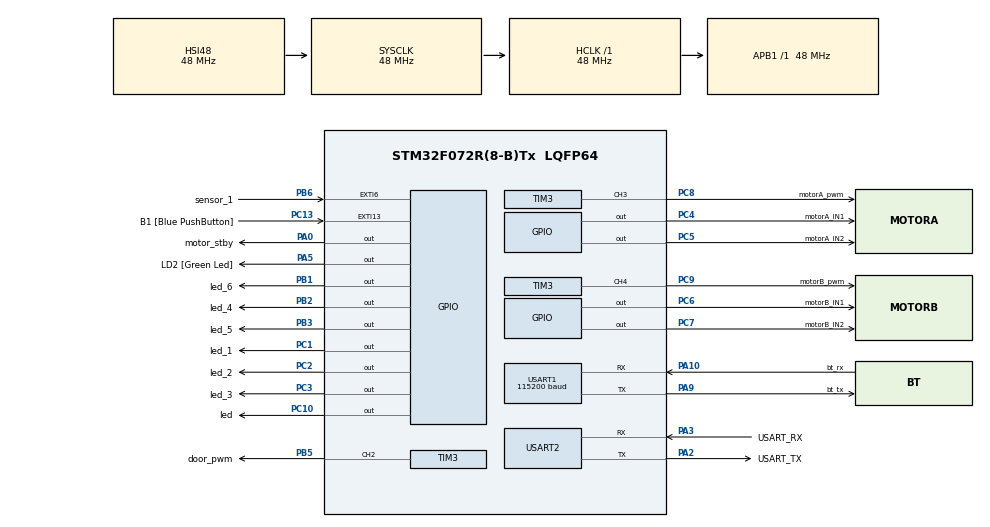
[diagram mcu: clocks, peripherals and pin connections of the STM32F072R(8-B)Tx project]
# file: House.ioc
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Mcu.Family=STM32F0
Mcu.Name=STM32F072R(8-B)Tx
Mcu.Package=LQFP64
NVIC.EXTI4_15_IRQn=true\:3\:0\:true\:false\:true\:true\:false
NVIC.USART1_IRQn=true\:3\:0\:true\:false\:true\:true\:false
PA0.GPIO_Label=motor_stby
PA0.PinState=GPIO_PIN_SET
PA0.Signal=GPIO_Output
PA10.GPIO_Label=bt_rx
PA10.Mode=Asynchronous
PA10.Signal=USART1_RX
PA13.GPIO_Label=TMS
PA13.Mode=Serial_Wire
PA13.Signal=SYS_SWDIO
PA14.GPIO_Label=TCK
PA14.Mode=Serial_Wire
PA14.Signal=SYS_SWCLK
PA2.GPIO_Label=USART_TX
PA2.GPIO_Mode=GPIO_MODE_AF_PP
PA2.GPIO_PuPd=GPIO_NOPULL
PA2.GPIO_Speed=GPIO_SPEED_FREQ_LOW
PA2.Mode=Asynchronous
PA2.Signal=USART2_TX
PA3.GPIO_Label=USART_RX
PA3.GPIO_Mode=GPIO_MODE_AF_PP
PA3.GPIO_PuPd=GPIO_NOPULL
PA3.GPIO_Speed=GPIO_SPEED_FREQ_LOW
PA3.Mode=Asynchronous
PA3.Signal=USART2_RX
PA5.GPIO_Label=LD2 [Green Led]
PA5.GPIO_Mode=GPIO_MODE_OUTPUT_PP
PA5.GPIO_PuPd=GPIO_NOPULL
PA5.GPIO_Speed=GPIO_SPEED_FREQ_LOW
PA5.Signal=GPIO_Output
PA9.GPIO_Label=bt_tx
PA9.Mode=Asynchronous
PA9.Signal=USART1_TX
PB1.GPIO_Label=led_6
PB1.Signal=GPIO_Output
PB2.GPIO_Label=led_4
PB2.GPIO_Speed=GPIO_SPEED_FREQ_LOW
PB2.Signal=GPIO_Output
PB3.GPIO_Label=led_5
PB3.Signal=GPIO_Output
PB5.GPIO_Label=door_pwm
PB5.Signal=S_TIM3_CH2
PB6.GPIO_Label=sensor_1
PB6.GPIO_ModeDefaultEXTI=GPIO_MODE_IT_RISING_FALLING
PB6.Signal=GPXTI6
PC1.GPIO_Label=led_1
PC1.GPIO_Speed=GPIO_SPEED_FREQ_LOW
PC1.Signal=GPIO_Output
PC10.GPIO_Label=led
PC10.Signal=GPIO_Output
PC13.GPIO_Label=B1 [Blue PushButton]
PC13.GPIO_ModeDefaultEXTI=GPIO_MODE_IT_FALLING
PC13.Signal=GPXTI13
PC14-OSC32_IN.Mode=LSE-External-Oscillator
PC14-OSC32_IN.Signal=RCC_OSC32_IN
PC15-OSC32_OUT.Mode=LSE-External-Oscillator
PC15-OSC32_OUT.Signal=RCC_OSC32_OUT
PC2.GPIO_Label=led_2
PC2.GPIO_Speed=GPIO_SPEED_FREQ_LOW
PC2.Signal=GPIO_Output
PC3.GPIO_Label=led_3
PC3.GPIO_Speed=GPIO_SPEED_FREQ_LOW
PC3.Signal=GPIO_Output
PC4.GPIO_Label=motorA_IN1
PC4.Signal=GPIO_Output
PC5.GPIO_Label=motorA_IN2
PC5.Signal=GPIO_Output
PC6.GPIO_Label=motorB_IN1
PC6.Signal=GPIO_Output
PC7.GPIO_Label=motorB_IN2
PC7.Signal=GPIO_Output
PC8.GPIO_Label=motorA_pwm
PC8.Signal=S_TIM3_CH3
PC9.GPIO_Label=motorB_pwm
PC9.Signal=S_TIM3_CH4
PF0-OSC_IN.Mode=HSE-External-Clock-Source
PF0-OSC_IN.Signal=RCC_OSC_IN
PF1-OSC_OUT.Signal=RCC_OSC_OUT
ProjectManager.HeapSize=0x200
ProjectManager.StackSize=0x400
ProjectManager.TargetToolchain=MDK-ARM V5.32
RCC.AHBFreq_Value=48000000
RCC.APB1Freq_Value=48000000
RCC.APB1TimFreq_Value=48000000
RCC.FLatency-AdvancedSettings=FLASH_LATENCY_1
RCC.HCLKFreq_Value=48000000
RCC.PLLDivider=RCC_PREDIV_DIV2
RCC.PLLMUL=RCC_PLL_MUL12
RCC.PREFETCH_ENABLE-AdvancedSettings=1
RCC.SYSCLKFreq_VALUE=48000000
RCC.SYSCLKSource=RCC_SYSCLKSOURCE_HSI48
SH.S_TIM3_CH2.0=TIM3_CH2,PWM Generation2 CH2
SH.S_TIM3_CH3.0=TIM3_CH3,PWM Generation3 CH3
SH.S_TIM3_CH4.0=TIM3_CH4,PWM Generation4 CH4
TIM3.AutoReloadPreload=TIM_AUTORELOAD_PRELOAD_ENABLE
TIM3.Channel-PWM\ Generation2\ CH2=TIM_CHANNEL_2
TIM3.Channel-PWM\ Generation3\ CH3=TIM_CHANNEL_3
TIM3.Channel-PWM\ Generation4\ CH4=TIM_CHANNEL_4
TIM3.Period=100-1
TIM3.Prescaler=480-1
USART1.BaudRate=115200
USART1.VirtualMode-Asynchronous=VM_ASYNC
USART2.VirtualMode=VM_ASYNC
USART2.VirtualMode-Asynchronous=VM_ASYNC
board=NUCLEO-F072RB

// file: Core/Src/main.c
/* USER CODE BEGIN Header */
/**
  ******************************************************************************
  * @file           : main.c
  * @brief          : Main program body
  ******************************************************************************
  * @attention
  *
  * <h2><center>&copy; Copyright (c) 2023 STMicroelectronics.
  * All rights reserved.</center></h2>
  *
  * This software component is licensed by ST under BSD 3-Clause license,
  * the "License"; You may not use this file except in compliance with the
  * License. You may obtain a copy of the License at:
  *                        opensource.org/licenses/BSD-3-Clause
  *
  ******************************************************************************
  */
/* USER CODE END Header */
#include "main.h"

/* USER CODE BEGIN Includes */
 #include <stdio.h>
 #include <stdbool.h>
 #include "led_control.h"
 #include "timer.h"
 #include "motor_direction.h"
 #include "door_control.h"
/* USER CODE END Includes */

TIM_HandleTypeDef htim3;

UART_HandleTypeDef huart1;
UART_HandleTypeDef huart2;

void SystemClock_Config(void);
static void MX_GPIO_Init(void);
static void MX_USART2_UART_Init(void);
static void MX_TIM3_Init(void);
static void MX_USART1_UART_Init(void);

int main(void)
{

  /* MCU Configuration--------------------------------------------------------*/

  /* Reset of all peripherals, Initializes the Flash interface and the Systick. */
  HAL_Init();

  /* Configure the system clock */
  SystemClock_Config();

  /* Initialize all configured peripherals */
  MX_GPIO_Init();
  MX_USART2_UART_Init();
  MX_TIM3_Init();
  MX_USART1_UART_Init();
  /* USER CODE BEGIN 2 */
 printf("Timer_control. \n\r");
 sensor1_on= false;
 printf("led control.\n\r");
 	printf("motor control.\n\r");
//	HAL_GPIO_WritePin(GPIOC,GPIO_PIN_1,GPIO_PIN_RESET);
//	HAL_Delay(1000);
//	HAL_GPIO_WritePin(GPIOC,GPIO_PIN_1,GPIO_PIN_SET);
//	HAL_Delay(1000);

	enablePWM_ch3();
	//pwmLevel_ch3(600);
	enablePWM_ch4();
	//pwmLevel_ch4(600);

  /* USER CODE END 2 */

  /* Infinite loop */
  while (1)
  {

  }
}

void SystemClock_Config(void)
{
  RCC_OscInitTypeDef RCC_OscInitStruct = {0};
  RCC_ClkInitTypeDef RCC_ClkInitStruct = {0};
  RCC_PeriphCLKInitTypeDef PeriphClkInit = {0};

  /** Initializes the RCC Oscillators according to the specified parameters
  * in the RCC_OscInitTypeDef structure.
  */
  RCC_OscInitStruct.OscillatorType = RCC_OSCILLATORTYPE_HSI48;
  RCC_OscInitStruct.HSI48State = RCC_HSI48_ON;
  RCC_OscInitStruct.PLL.PLLState = RCC_PLL_NONE;
  if (HAL_RCC_OscConfig(&RCC_OscInitStruct) != HAL_OK)
  {
    Error_Handler();
  }
  /** Initializes the CPU, AHB and APB buses clocks
  */
  RCC_ClkInitStruct.ClockType = RCC_CLOCKTYPE_HCLK|RCC_CLOCKTYPE_SYSCLK
                              |RCC_CLOCKTYPE_PCLK1;
  RCC_ClkInitStruct.SYSCLKSource = RCC_SYSCLKSOURCE_HSI48;
  RCC_ClkInitStruct.AHBCLKDivider = RCC_SYSCLK_DIV1;
  RCC_ClkInitStruct.APB1CLKDivider = RCC_HCLK_DIV1;

  if (HAL_RCC_ClockConfig(&RCC_ClkInitStruct, FLASH_LATENCY_1) != HAL_OK)
  {
    Error_Handler();
  }
  PeriphClkInit.PeriphClockSelection = RCC_PERIPHCLK_USART1|RCC_PERIPHCLK_USART2;
  PeriphClkInit.Usart1ClockSelection = RCC_USART1CLKSOURCE_PCLK1;
  PeriphClkInit.Usart2ClockSelection = RCC_USART2CLKSOURCE_PCLK1;
  if (HAL_RCCEx_PeriphCLKConfig(&PeriphClkInit) != HAL_OK)
  {
    Error_Handler();
  }
}

static void MX_TIM3_Init(void)
{

  TIM_MasterConfigTypeDef sMasterConfig = {0};
  TIM_OC_InitTypeDef sConfigOC = {0};

  htim3.Instance = TIM3;
  htim3.Init.Prescaler = 480-1;
  htim3.Init.CounterMode = TIM_COUNTERMODE_UP;
  htim3.Init.Period = 100-1;
  htim3.Init.ClockDivision = TIM_CLOCKDIVISION_DIV1;
  htim3.Init.AutoReloadPreload = TIM_AUTORELOAD_PRELOAD_ENABLE;
  if (HAL_TIM_PWM_Init(&htim3) != HAL_OK)
  {
    Error_Handler();
  }
  sMasterConfig.MasterOutputTrigger = TIM_TRGO_RESET;
  sMasterConfig.MasterSlaveMode = TIM_MASTERSLAVEMODE_DISABLE;
  if (HAL_TIMEx_MasterConfigSynchronization(&htim3, &sMasterConfig) != HAL_OK)
  {
    Error_Handler();
  }
  sConfigOC.OCMode = TIM_OCMODE_PWM1;
  sConfigOC.Pulse = 0;
  sConfigOC.OCPolarity = TIM_OCPOLARITY_HIGH;
  sConfigOC.OCFastMode = TIM_OCFAST_DISABLE;
  if (HAL_TIM_PWM_ConfigChannel(&htim3, &sConfigOC, TIM_CHANNEL_2) != HAL_OK)
  {
    Error_Handler();
  }
  if (HAL_TIM_PWM_ConfigChannel(&htim3, &sConfigOC, TIM_CHANNEL_3) != HAL_OK)
  {
    Error_Handler();
  }
  if (HAL_TIM_PWM_ConfigChannel(&htim3, &sConfigOC, TIM_CHANNEL_4) != HAL_OK)
  {
    Error_Handler();
  }
  HAL_TIM_MspPostInit(&htim3);

}

static void MX_USART1_UART_Init(void)
{

  huart1.Instance = USART1;
  huart1.Init.BaudRate = 115200;
  huart1.Init.WordLength = UART_WORDLENGTH_8B;
  huart1.Init.StopBits = UART_STOPBITS_1;
  huart1.Init.Parity = UART_PARITY_NONE;
  huart1.Init.Mode = UART_MODE_TX_RX;
  huart1.Init.HwFlowCtl = UART_HWCONTROL_NONE;
  huart1.Init.OverSampling = UART_OVERSAMPLING_16;
  huart1.Init.OneBitSampling = UART_ONE_BIT_SAMPLE_DISABLE;
  huart1.AdvancedInit.AdvFeatureInit = UART_ADVFEATURE_NO_INIT;
  if (HAL_UART_Init(&huart1) != HAL_OK)
  {
    Error_Handler();
  }
  /* USER CODE BEGIN USART1_Init 2 */
	USART1->CR1 |= 0x1ul<<5;
	USART1->ICR |= 0x1ul<<6;
  /* USER CODE END USART1_Init 2 */

}

static void MX_USART2_UART_Init(void)
{

  huart2.Instance = USART2;
  huart2.Init.BaudRate = 38400;
  huart2.Init.WordLength = UART_WORDLENGTH_8B;
  huart2.Init.StopBits = UART_STOPBITS_1;
  huart2.Init.Parity = UART_PARITY_NONE;
  huart2.Init.Mode = UART_MODE_TX_RX;
  huart2.Init.HwFlowCtl = UART_HWCONTROL_NONE;
  huart2.Init.OverSampling = UART_OVERSAMPLING_16;
  huart2.Init.OneBitSampling = UART_ONE_BIT_SAMPLE_DISABLE;
  huart2.AdvancedInit.AdvFeatureInit = UART_ADVFEATURE_NO_INIT;
  if (HAL_UART_Init(&huart2) != HAL_OK)
  {
    Error_Handler();
  }

}

static void MX_GPIO_Init(void)
{
  GPIO_InitTypeDef GPIO_InitStruct = {0};

  /* GPIO Ports Clock Enable */
  __HAL_RCC_GPIOC_CLK_ENABLE();
  __HAL_RCC_GPIOF_CLK_ENABLE();
  __HAL_RCC_GPIOA_CLK_ENABLE();
  __HAL_RCC_GPIOB_CLK_ENABLE();

  /*Configure GPIO pin Output Level */
  HAL_GPIO_WritePin(GPIOC, led_1_Pin|led_2_Pin|led_3_Pin|motorA_IN1_Pin
                          |motorA_IN2_Pin|motorB_IN1_Pin|motorB_IN2_Pin|led_Pin, GPIO_PIN_RESET);

  /*Configure GPIO pin Output Level */
  HAL_GPIO_WritePin(motor_stby_GPIO_Port, motor_stby_Pin, GPIO_PIN_SET);

  /*Configure GPIO pin Output Level */
  HAL_GPIO_WritePin(LD2_GPIO_Port, LD2_Pin, GPIO_PIN_RESET);

  /*Configure GPIO pin Output Level */
  HAL_GPIO_WritePin(GPIOB, led_6_Pin|led_4_Pin|led_5_Pin, GPIO_PIN_RESET);

  /*Configure GPIO pin : B1_Pin */
  GPIO_InitStruct.Pin = B1_Pin;
  GPIO_InitStruct.Mode = GPIO_MODE_IT_FALLING;
  GPIO_InitStruct.Pull = GPIO_NOPULL;
  HAL_GPIO_Init(B1_GPIO_Port, &GPIO_InitStruct);

  /*Configure GPIO pins : led_1_Pin led_2_Pin led_3_Pin motorA_IN1_Pin
                           motorA_IN2_Pin motorB_IN1_Pin motorB_IN2_Pin led_Pin */
  GPIO_InitStruct.Pin = led_1_Pin|led_2_Pin|led_3_Pin|motorA_IN1_Pin
                          |motorA_IN2_Pin|motorB_IN1_Pin|motorB_IN2_Pin|led_Pin;
  GPIO_InitStruct.Mode = GPIO_MODE_OUTPUT_PP;
  GPIO_InitStruct.Pull = GPIO_NOPULL;
  GPIO_InitStruct.Speed = GPIO_SPEED_FREQ_LOW;
  HAL_GPIO_Init(GPIOC, &GPIO_InitStruct);

  /*Configure GPIO pins : motor_stby_Pin LD2_Pin */
  GPIO_InitStruct.Pin = motor_stby_Pin|LD2_Pin;
  GPIO_InitStruct.Mode = GPIO_MODE_OUTPUT_PP;
  GPIO_InitStruct.Pull = GPIO_NOPULL;
  GPIO_InitStruct.Speed = GPIO_SPEED_FREQ_LOW;
  HAL_GPIO_Init(GPIOA, &GPIO_InitStruct);

  /*Configure GPIO pins : led_6_Pin led_4_Pin led_5_Pin */
  GPIO_InitStruct.Pin = led_6_Pin|led_4_Pin|led_5_Pin;
  GPIO_InitStruct.Mode = GPIO_MODE_OUTPUT_PP;
  GPIO_InitStruct.Pull = GPIO_NOPULL;
  GPIO_InitStruct.Speed = GPIO_SPEED_FREQ_LOW;
  HAL_GPIO_Init(GPIOB, &GPIO_InitStruct);

  /*Configure GPIO pin : sensor_1_Pin */
  GPIO_InitStruct.Pin = sensor_1_Pin;
  GPIO_InitStruct.Mode = GPIO_MODE_IT_RISING_FALLING;
  GPIO_InitStruct.Pull = GPIO_NOPULL;
  HAL_GPIO_Init(sensor_1_GPIO_Port, &GPIO_InitStruct);

  /* EXTI interrupt init*/
  HAL_NVIC_SetPriority(EXTI4_15_IRQn, 3, 0);
  HAL_NVIC_EnableIRQ(EXTI4_15_IRQn);

}

void Error_Handler(void)
{
  __disable_irq();
  while (1)
  {
  }
}

/************************ (C) COPYRIGHT STMicroelectronics *****END OF FILE****/
